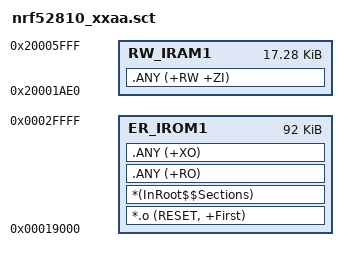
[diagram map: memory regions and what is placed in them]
; *************************************************************
; *** Scatter-Loading Description File generated by uVision ***
; *************************************************************

LR_IROM1 0x00019000 0x00017000  {    ; load region size_region
  ER_IROM1 0x00019000 0x00017000  {  ; load address = execution address
   *.o (RESET, +First)
   *(InRoot$$Sections)
   .ANY (+RO)
   .ANY (+XO)
  }
  RW_IRAM1 0x20001AE0 0x00004520  {  ; RW data
   .ANY (+RW +ZI)
  }
}

